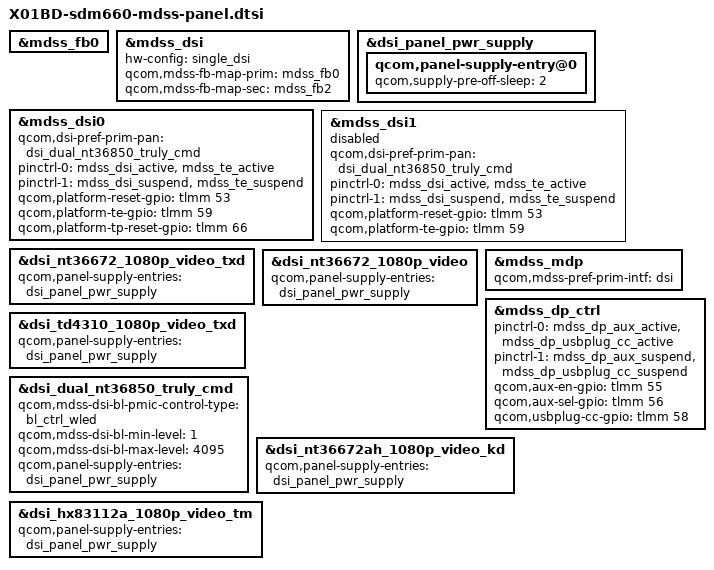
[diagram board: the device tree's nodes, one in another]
/* Copyright (c) 2017, The Linux Foundation. All rights reserved.
 *
 * This program is free software; you can redistribute it and/or modify
 * it under the terms of the GNU General Public License version 2 and
 * only version 2 as published by the Free Software Foundation.
 *
 * This program is distributed in the hope that it will be useful,
 * but WITHOUT ANY WARRANTY; without even the implied warranty of
 * MERCHANTABILITY or FITNESS FOR A PARTICULAR PURPOSE.  See the
 * GNU General Public License for more details.
 */

#include "dsi-panel-auo-ft8716f-5p9-fhd-video.dtsi"
#include "dsi-panel-nt36672-1080p-video-txd.dtsi"
#include "dsi-panel-nt36672-1080p-video.dtsi"
#include "dsi-panel-td4310-1080p-video-txd.dtsi"
#include "dsi-panel-hx83112a-1080p-video-tm.dtsi"
#include "dsi-panel-nt36672ah-1080p-video-kd.dtsi"

&mdss_fb0 {
	/delete-property/ qcom,mdss-mixer-swap;
};

&mdss_dsi {
	hw-config = "single_dsi";
	qcom,mdss-fb-map-prim = <&mdss_fb0>;
	qcom,mdss-fb-map-sec = <&mdss_fb2>;
};

&dsi_panel_pwr_supply {
	qcom,panel-supply-entry@0 {
	qcom,supply-pre-off-sleep = <2>;
	};
};

&mdss_dsi0 {
	qcom,dsi-pref-prim-pan = <&dsi_nt36672_1080p_video_txd>;
};

&mdss_dsi1 {
	status = "disabled";
	qcom,dsi-pref-prim-pan = <&dsi_nt36672_1080p_video_txd>;
};

&dsi_nt36672_1080p_video_txd {
  qcom,panel-supply-entries = <&dsi_panel_pwr_supply>;
};

&dsi_nt36672_1080p_video {
  qcom,panel-supply-entries = <&dsi_panel_pwr_supply>;
};

&dsi_td4310_1080p_video_txd {
	qcom,panel-supply-entries = <&dsi_panel_pwr_supply>;
};

&mdss_mdp {
	qcom,mdss-pref-prim-intf = "dsi";
};

&mdss_dp_ctrl {
	pinctrl-names = "mdss_dp_active", "mdss_dp_sleep";
	pinctrl-0 = <&mdss_dp_aux_active &mdss_dp_usbplug_cc_active>;
	pinctrl-1 = <&mdss_dp_aux_suspend &mdss_dp_usbplug_cc_suspend>;
	qcom,aux-en-gpio = <&tlmm 55 0>;
	qcom,aux-sel-gpio = <&tlmm 56 0>;
	qcom,usbplug-cc-gpio = <&tlmm 58 0>;
};

&mdss_dsi {
	hw-config = "single_dsi";
};

&mdss_dsi0 {
	qcom,dsi-pref-prim-pan = <&dsi_dual_nt36850_truly_cmd>;
	pinctrl-names = "mdss_default", "mdss_sleep";
	pinctrl-0 = <&mdss_dsi_active &mdss_te_active>;
	pinctrl-1 = <&mdss_dsi_suspend &mdss_te_suspend>;
	qcom,platform-reset-gpio = <&tlmm 53 0>;
	qcom,platform-te-gpio = <&tlmm 59 0>;
	qcom,platform-tp-reset-gpio = <&tlmm 66 0>;
};

&mdss_dsi1 {
	status = "disabled";
	qcom,dsi-pref-prim-pan = <&dsi_dual_nt36850_truly_cmd>;
	pinctrl-names = "mdss_default", "mdss_sleep";
	pinctrl-0 = <&mdss_dsi_active &mdss_te_active>;
	pinctrl-1 = <&mdss_dsi_suspend &mdss_te_suspend>;
	qcom,platform-reset-gpio = <&tlmm 53 0>;
	qcom,platform-te-gpio = <&tlmm 59 0>;
};

&dsi_dual_nt36850_truly_cmd {
	qcom,mdss-dsi-bl-pmic-control-type = "bl_ctrl_wled";
	qcom,mdss-dsi-bl-min-level = <1>;
	qcom,mdss-dsi-bl-max-level = <4095>;
	qcom,panel-supply-entries = <&dsi_panel_pwr_supply>;
};

&dsi_nt36672_1080p_video_txd {
	qcom,panel-supply-entries = <&dsi_panel_pwr_supply>;
};
&dsi_nt36672_1080p_video {
	qcom,panel-supply-entries = <&dsi_panel_pwr_supply>;
};

&dsi_nt36672ah_1080p_video_kd {
	qcom,panel-supply-entries = <&dsi_panel_pwr_supply>;
};

&dsi_hx83112a_1080p_video_tm {
	qcom,panel-supply-entries = <&dsi_panel_pwr_supply>;
};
